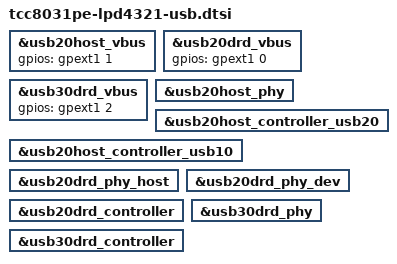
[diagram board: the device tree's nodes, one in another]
// SPDX-License-Identifier: (GPL-2.0-or-later OR MIT)
/*
 * Copyright (C) Telechips Inc.
 */

&usb20host_vbus {
	gpios = <&gpext1 1 0x0>;
	status = "okay";
};

&usb20drd_vbus {
	gpios = <&gpext1 0 0x0>;
	status = "okay";
};

&usb30drd_vbus {
	gpios = <&gpext1 2 0x0>;
	status = "okay";
};

&usb20host_phy {
	status = "okay";
};

&usb20host_controller_usb20 {
	status = "okay";
};

&usb20host_controller_usb10 {
	status = "okay";
};

&usb20drd_phy_host {
	status = "okay";
};

&usb20drd_phy_dev {
	status = "okay";
};

&usb20drd_controller {
	status = "okay";
};

&usb30drd_phy {
	status = "okay";
};

&usb30drd_controller {
	status = "okay";
};
